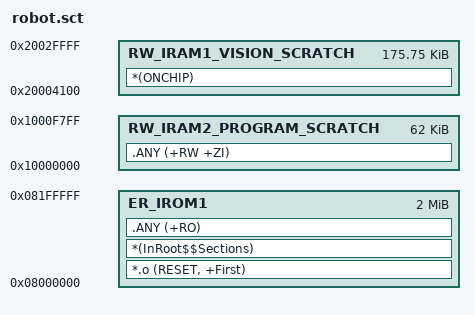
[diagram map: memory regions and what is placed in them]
; *************************************************************
; *** Scatter-Loading File for Cozmo - do not edit (Kilroy was here)
; *************************************************************

LR_IROM1 0x08000000 0x00200000  {    ; load region size_region

; Read-only data and code
  ER_IROM1 0x08000000 0x00200000  {  ; load address = execution address
    *.o (RESET, +First)
    *(InRoot$$Sections)
    .ANY (+RO)
  }

; Reserve 16KB for stack + 256 bytes for (unused) heap
; 0x20000000 0x0004100

; On-chip memory - available for DMA
  RW_IRAM1_VISION_SCRATCH 0x20004100 0x0002BF00  {
    *(ONCHIP)
  }

; Default for most variables/etc - not supporting DMA
  RW_IRAM2_PROGRAM_SCRATCH 0x10000000 0x0000F800  {
    .ANY (+RW +ZI)
  }
}
